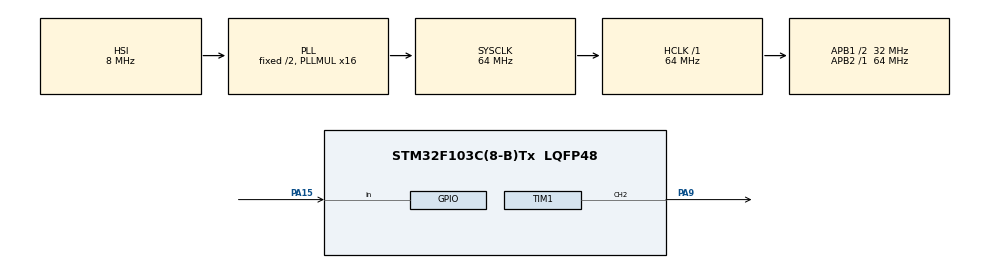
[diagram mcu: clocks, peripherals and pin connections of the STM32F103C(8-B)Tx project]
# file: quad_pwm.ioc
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Mcu.Family=STM32F1
Mcu.Name=STM32F103C(8-B)Tx
Mcu.Package=LQFP48
NVIC.PriorityGroup=NVIC_PRIORITYGROUP_4
PA13.Mode=Serial_Wire
PA13.Signal=SYS_JTMS-SWDIO
PA14.Mode=Serial_Wire
PA14.Signal=SYS_JTCK-SWCLK
PA15.Signal=GPIO_Input
PA9.Signal=S_TIM1_CH2
ProjectManager.HeapSize=0x200
ProjectManager.StackSize=0x400
ProjectManager.TargetToolchain=CMake
RCC.AHBFreq_Value=64000000
RCC.APB1CLKDivider=RCC_HCLK_DIV2
RCC.APB1Freq_Value=32000000
RCC.APB1TimFreq_Value=64000000
RCC.APB2Freq_Value=64000000
RCC.APB2TimFreq_Value=64000000
RCC.HCLKFreq_Value=64000000
RCC.PLLMUL=RCC_PLL_MUL16
RCC.SYSCLKFreq_VALUE=64000000
RCC.SYSCLKSource=RCC_SYSCLKSOURCE_PLLCLK
RCC.USBFreq_Value=64000000
SH.S_TIM1_CH2.0=TIM1_CH2,PWM Generation2 CH2
TIM1.Channel-PWM\ Generation2\ CH2=TIM_CHANNEL_2
TIM1.Period=63
TIM1.Prescaler=999
VP_TIM1_VS_ClockSourceINT.Mode=Internal
board=custom

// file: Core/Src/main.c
/* USER CODE BEGIN Header */
/**
  ******************************************************************************
  * @file           : main.c
  * @brief          : Main program body
  ******************************************************************************
  * @attention
  *
  * Copyright (c) 2026 STMicroelectronics.
  * All rights reserved.
  *
  * This software is licensed under terms that can be found in the LICENSE file
  * in the root directory of this software component.
  * If no LICENSE file comes with this software, it is provided AS-IS.
  *
  ******************************************************************************
  */
/* USER CODE END Header */
#include "main.h"

/* USER CODE BEGIN Includes */
#include "math.h"
#include "stm32f103xb.h"
#include "stm32f1xx_hal.h"
#include "stm32f1xx_hal_gpio.h"
#include <stdint.h>
/* USER CODE END Includes */

/* USER CODE BEGIN PTD */
typedef enum {
  idle,
  pressed,
  hold_down,
  released
} button_state;

typedef struct{
  uint32_t pin;
  GPIO_TypeDef* port;
  button_state state;
} button_t;
/* USER CODE END PTD */

/* USER CODE BEGIN PD */
#define BUTTON_PIN  GPIO_PIN_15
#define BUTTON_PORT GPIOA

#define CLOCK_FREQ (64 * pow(10,6)) // 64MHz

#define PWM0_FREQ  (1  * pow(10,3)) // 1KHz
#define PWM1_FREQ  (10 * pow(10,3)) // 10KHz
#define PWM2_FREQ  (20 * pow(10,3)) // 20KHz
#define PWM3_FREQ  (50 * pow(10,3)) // 50KHz

#define AUTORELOAD 63

#define PWM0_PRESCALE ((CLOCK_FREQ / ((PWM0_FREQ) * (AUTORELOAD + 1))) - 1)
#define PWM1_PRESCALE ((CLOCK_FREQ / ((PWM1_FREQ) * (AUTORELOAD + 1))) - 1)
#define PWM2_PRESCALE ((CLOCK_FREQ / ((PWM2_FREQ) * (AUTORELOAD + 1))) - 1)
#define PWM3_PRESCALE ((CLOCK_FREQ / ((PWM3_FREQ) * (AUTORELOAD + 1))) - 1)

#define PERIPHERAL_ADDR 0x40000000

#define TIMER1_ADDR (0x12C00 + PERIPHERAL_ADDR)

#define TIMER1_PRESCALE_REG_ADDR (0x28 + TIMER1_ADDR)
/* USER CODE END PD */

TIM_HandleTypeDef htim1;

/* USER CODE BEGIN PV */
uint32_t pwm_current = 0;

uint32_t* prescaler_reg = (uint32_t*) TIMER1_PRESCALE_REG_ADDR;
/* USER CODE END PV */

void SystemClock_Config(void);
static void MX_GPIO_Init(void);
static void MX_TIM1_Init(void);
/* USER CODE BEGIN PFP */
void update_pwm(button_t* button);
void button_state_update(button_t* button);
/* USER CODE END PFP */

int main(void)
{

  /* MCU Configuration--------------------------------------------------------*/

  /* Reset of all peripherals, Initializes the Flash interface and the Systick. */
  HAL_Init();

  /* Configure the system clock */
  SystemClock_Config();

  /* Initialize all configured peripherals */
  MX_GPIO_Init();
  MX_TIM1_Init();
  /* USER CODE BEGIN 2 */
  HAL_TIM_PWM_Start(&htim1, TIM_CHANNEL_2);
  button_t button = {BUTTON_PIN, BUTTON_PORT, idle};
  /* USER CODE END 2 */

  /* Infinite loop */
  /* USER CODE BEGIN WHILE */
  while (1)
  {
    update_pwm(&button);
    /* USER CODE END WHILE */

  }
}

void SystemClock_Config(void)
{
  RCC_OscInitTypeDef RCC_OscInitStruct = {0};
  RCC_ClkInitTypeDef RCC_ClkInitStruct = {0};

  /** Initializes the RCC Oscillators according to the specified parameters
  * in the RCC_OscInitTypeDef structure.
  */
  RCC_OscInitStruct.OscillatorType = RCC_OSCILLATORTYPE_HSI;
  RCC_OscInitStruct.HSIState = RCC_HSI_ON;
  RCC_OscInitStruct.HSICalibrationValue = RCC_HSICALIBRATION_DEFAULT;
  RCC_OscInitStruct.PLL.PLLState = RCC_PLL_ON;
  RCC_OscInitStruct.PLL.PLLSource = RCC_PLLSOURCE_HSI_DIV2;
  RCC_OscInitStruct.PLL.PLLMUL = RCC_PLL_MUL16;
  if (HAL_RCC_OscConfig(&RCC_OscInitStruct) != HAL_OK)
  {
    Error_Handler();
  }

  /** Initializes the CPU, AHB and APB buses clocks
  */
  RCC_ClkInitStruct.ClockType = RCC_CLOCKTYPE_HCLK|RCC_CLOCKTYPE_SYSCLK
                              |RCC_CLOCKTYPE_PCLK1|RCC_CLOCKTYPE_PCLK2;
  RCC_ClkInitStruct.SYSCLKSource = RCC_SYSCLKSOURCE_PLLCLK;
  RCC_ClkInitStruct.AHBCLKDivider = RCC_SYSCLK_DIV1;
  RCC_ClkInitStruct.APB1CLKDivider = RCC_HCLK_DIV2;
  RCC_ClkInitStruct.APB2CLKDivider = RCC_HCLK_DIV1;

  if (HAL_RCC_ClockConfig(&RCC_ClkInitStruct, FLASH_LATENCY_2) != HAL_OK)
  {
    Error_Handler();
  }
}

static void MX_TIM1_Init(void)
{

  TIM_ClockConfigTypeDef sClockSourceConfig = {0};
  TIM_MasterConfigTypeDef sMasterConfig = {0};
  TIM_OC_InitTypeDef sConfigOC = {0};
  TIM_BreakDeadTimeConfigTypeDef sBreakDeadTimeConfig = {0};

  htim1.Instance = TIM1;
  htim1.Init.Prescaler = 999;
  htim1.Init.CounterMode = TIM_COUNTERMODE_UP;
  htim1.Init.Period = 63;
  htim1.Init.ClockDivision = TIM_CLOCKDIVISION_DIV1;
  htim1.Init.RepetitionCounter = 0;
  htim1.Init.AutoReloadPreload = TIM_AUTORELOAD_PRELOAD_DISABLE;
  if (HAL_TIM_Base_Init(&htim1) != HAL_OK)
  {
    Error_Handler();
  }
  sClockSourceConfig.ClockSource = TIM_CLOCKSOURCE_INTERNAL;
  if (HAL_TIM_ConfigClockSource(&htim1, &sClockSourceConfig) != HAL_OK)
  {
    Error_Handler();
  }
  if (HAL_TIM_PWM_Init(&htim1) != HAL_OK)
  {
    Error_Handler();
  }
  sMasterConfig.MasterOutputTrigger = TIM_TRGO_RESET;
  sMasterConfig.MasterSlaveMode = TIM_MASTERSLAVEMODE_DISABLE;
  if (HAL_TIMEx_MasterConfigSynchronization(&htim1, &sMasterConfig) != HAL_OK)
  {
    Error_Handler();
  }
  sConfigOC.OCMode = TIM_OCMODE_PWM1;
  sConfigOC.Pulse = 32;
  sConfigOC.OCPolarity = TIM_OCPOLARITY_HIGH;
  sConfigOC.OCNPolarity = TIM_OCNPOLARITY_HIGH;
  sConfigOC.OCFastMode = TIM_OCFAST_DISABLE;
  sConfigOC.OCIdleState = TIM_OCIDLESTATE_RESET;
  sConfigOC.OCNIdleState = TIM_OCNIDLESTATE_RESET;
  if (HAL_TIM_PWM_ConfigChannel(&htim1, &sConfigOC, TIM_CHANNEL_2) != HAL_OK)
  {
    Error_Handler();
  }
  sBreakDeadTimeConfig.OffStateRunMode = TIM_OSSR_DISABLE;
  sBreakDeadTimeConfig.OffStateIDLEMode = TIM_OSSI_DISABLE;
  sBreakDeadTimeConfig.LockLevel = TIM_LOCKLEVEL_OFF;
  sBreakDeadTimeConfig.DeadTime = 0;
  sBreakDeadTimeConfig.BreakState = TIM_BREAK_DISABLE;
  sBreakDeadTimeConfig.BreakPolarity = TIM_BREAKPOLARITY_HIGH;
  sBreakDeadTimeConfig.AutomaticOutput = TIM_AUTOMATICOUTPUT_DISABLE;
  if (HAL_TIMEx_ConfigBreakDeadTime(&htim1, &sBreakDeadTimeConfig) != HAL_OK)
  {
    Error_Handler();
  }
  HAL_TIM_MspPostInit(&htim1);

}

static void MX_GPIO_Init(void)
{
  GPIO_InitTypeDef GPIO_InitStruct = {0};

  /* GPIO Ports Clock Enable */
  __HAL_RCC_GPIOA_CLK_ENABLE();

  /*Configure GPIO pin : PA15 */
  GPIO_InitStruct.Pin = GPIO_PIN_15;
  GPIO_InitStruct.Mode = GPIO_MODE_INPUT;
  GPIO_InitStruct.Pull = GPIO_NOPULL;
  HAL_GPIO_Init(GPIOA, &GPIO_InitStruct);

}

/* USER CODE BEGIN 4 */
void update_pwm(button_t* button){
  button_state_update(button);

  if(button->state == pressed){
    switch (pwm_current) {
      case 0:
        *prescaler_reg = PWM1_PRESCALE;
        pwm_current = 1;
        break;
      case 1:
        *prescaler_reg = PWM2_PRESCALE;
        pwm_current = 2;
        break;
      case 2:
        *prescaler_reg = PWM3_PRESCALE;
        pwm_current = 3;
        break;
      case 3:
        *prescaler_reg = PWM0_PRESCALE;
        pwm_current = 0;
        break;
    }
  }
}

void button_state_update(button_t* button){
  // 0 is the value received when the button is pressed
  if(HAL_GPIO_ReadPin(button->port, button->pin) == GPIO_PIN_RESET){
    // Debounce
    HAL_Delay(20);

    if(HAL_GPIO_ReadPin(button->port, button->pin) == GPIO_PIN_RESET){
      // Button is actually down
      // Only proceed if button was not already pressed
      switch (button->state) {
        case idle:
          button->state = pressed;
          break;
        case pressed:
          button->state = hold_down;
          break;
        case hold_down:
          break;
        case released:
          button->state = pressed;
        }

        return;
      }
    }

  switch (button->state){
      case idle:
        button->state = idle;
        break;
      case pressed:
        button->state = released;
        break;
      case hold_down:
        button->state = released;
        break;
      case released:
          button->state = idle;
    }
}
/* USER CODE END 4 */

void Error_Handler(void)
{
  __disable_irq();
  while (1)
  {
  }
}
